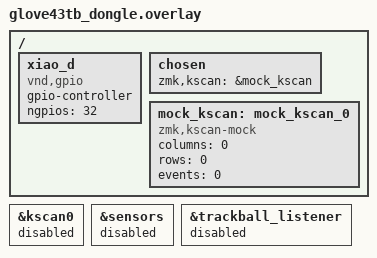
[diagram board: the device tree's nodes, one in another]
#include "glove43tb.dtsi"

/ {
    /* 1. 参照エラーを防ぐためのダミーインターフェース（仮想GPIO） */
    xiao_d: xiao_d {
        compatible = "vnd,gpio";
        gpio-controller;
        #gpio-cells = <2>;
        ngpios = <32>;
    };

    /* 2. キースキャンをダミー（Null0）に流すルーティング */
    chosen {
        zmk,kscan = &mock_kscan;
    };

    mock_kscan: mock_kscan_0 {
        compatible = "zmk,kscan-mock";
        columns = <0>;
        rows = <0>;
        events = <0>;
    };
};

/* 3. 物理デバイスが存在しないドライバ（サービス）の起動を強制オフにする */
&kscan0 {
    status = "disabled";
};

&sensors {
    status = "disabled";
};

&trackball_listener {
    status = "disabled";
};
